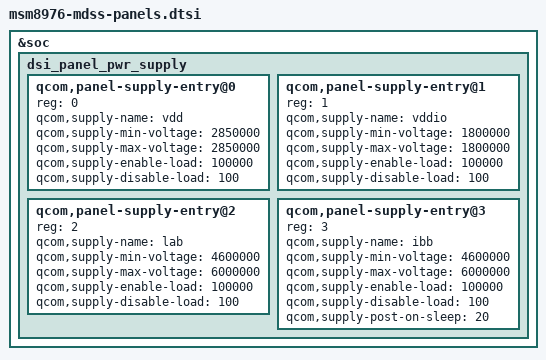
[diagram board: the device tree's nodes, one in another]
/* Copyright (c) 2015, The Linux Foundation. All rights reserved.
 *
 * This program is free software; you can redistribute it and/or modify
 * it under the terms of the GNU General Public License version 2 and
 * only version 2 as published by the Free Software Foundation.
 *
 * This program is distributed in the hope that it will be useful,
 * but WITHOUT ANY WARRANTY; without even the implied warranty of
 * MERCHANTABILITY or FITNESS FOR A PARTICULAR PURPOSE.  See the
 * GNU General Public License for more details.
 */

#include "dsi-panel-sim-video.dtsi"
#include "dsi-panel-sim-cmd.dtsi"
#include "dsi-panel-nt35597-dualmipi-wqxga-video.dtsi"
#include "dsi-panel-nt35597-dualmipi-wqxga-cmd.dtsi"
#include "dsi-panel-otm1906c-1080p-cmd.dtsi"
#include "dsi-panel-hx8399a-1080p-video.dtsi"
#include "dsi-panel-nt35597-dsc-wqxga-video.dtsi"
#include "dsi-panel-nt35597-dsc-wqxga-cmd.dtsi"
#include "dsi-panel-truly-1080p-video.dtsi"
#include "dsi-panel-truly-1080p-cmd.dtsi"
#include "dsi-panel-adv7533-1080p-video.dtsi"
#include "dsi-panel-adv7533-720p-video.dtsi"
#include "dsi-panel-nt35523-dualmipi-wqxga-video.dtsi"

&soc {
	dsi_panel_pwr_supply: dsi_panel_pwr_supply {
		#address-cells = <1>;
		#size-cells = <0>;

		qcom,panel-supply-entry@0 {
			reg = <0>;
			qcom,supply-name = "vdd";
			qcom,supply-min-voltage = <2850000>;
			qcom,supply-max-voltage = <2850000>;
			qcom,supply-enable-load = <100000>;
			qcom,supply-disable-load = <100>;
		};

		qcom,panel-supply-entry@1 {
			reg = <1>;
			qcom,supply-name = "vddio";
			qcom,supply-min-voltage = <1800000>;
			qcom,supply-max-voltage = <1800000>;
			qcom,supply-enable-load = <100000>;
			qcom,supply-disable-load = <100>;
		};

		qcom,panel-supply-entry@2 {
			reg = <2>;
			qcom,supply-name = "lab";
			qcom,supply-min-voltage = <4600000>;
			qcom,supply-max-voltage = <6000000>;
			qcom,supply-enable-load = <100000>;
			qcom,supply-disable-load = <100>;
		};

		qcom,panel-supply-entry@3 {
			reg = <3>;
			qcom,supply-name = "ibb";
			qcom,supply-min-voltage = <4600000>;
			qcom,supply-max-voltage = <6000000>;
			qcom,supply-enable-load = <100000>;
			qcom,supply-disable-load = <100>;
			qcom,supply-post-on-sleep = <20>;
		};
	};
};
